# DEBUGSS_WRAP_CSTPIU_CFG_0_000720004000h register map
Vendor: Texas Instruments
Peripheral module from a debugger description file (folder AM275x).
Registers are 32-bit, read-only, reset 0x0 unless marked. A register's access mark holds for its fields unless they carry their own. Offsets are as the file gives them; lines under a group give offsets from that group; [hi:lo] are bit positions; {n}, {i} and the like mark numbered series; 'fields as' and 'values as' point back to an identical list; <NAME> marks a mode.

## cstpiu_cfg_0
0x00 CSTPIU_CFG_0_SUPPORTSIZE reset 0xFFFFFFFF — This register indicates how many trace pins are available for export. One pin per bit, right justified
  [31:0] SUPPORTSIZEREG
0x04 CSTPIU_CFG_0_CURPORTSIZE rw reset 0x1 — The Current Port Size Register has the same format as the Supported Port Sizes register but only one bit is set, and all others must be zero
  [31:0] CURRENTPORTSIZE
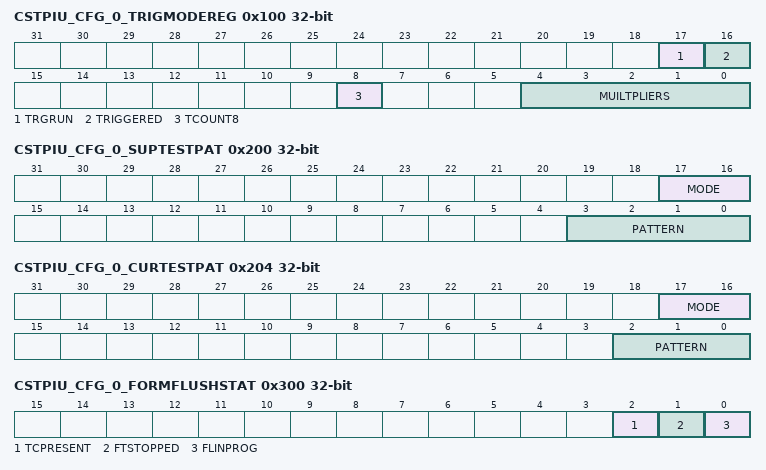
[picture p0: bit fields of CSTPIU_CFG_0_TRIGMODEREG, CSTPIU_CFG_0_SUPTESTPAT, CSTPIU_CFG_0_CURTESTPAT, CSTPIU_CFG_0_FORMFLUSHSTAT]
0x100 CSTPIU_CFG_0_TRIGMODEREG — This register indicates the implemented Trigger Counter multipliers and other supported features of the trigger system
  [17] TRGRUN — Trigger Counter running. A trigger has occurred but the counter is not at zero.
  [16] TRIGGERED — A trigger has occurred and the counter has reached zero.
  [8] TCOUNT8 — An 8-bit wide counter register implemented.
  [4:0] MUILTPLIERS — Multiply the Trigger Counter by 2, 4, 16, 256, 64K supported. Each bit is a mpy value.
0x104 CSTPIU_CFG_0_TRIGCTRREG access per field
  [7:0] TRIGCOUNT rw — 8-bit counter value for the number of words to be output from the formatter before a trigger is inserted.
0x108 CSTPIU_CFG_0_TRIGMPYREG access per field
  [4:0] MULTIPLIER rw — Trigger multiply value bit0=x2, bit1=x4, bit2=x16, bit3=x256, bit4=x64K.
0x200 CSTPIU_CFG_0_SUPTESTPAT — This register displays the supported patterns and modes for calibration
  [17:16] MODE — bit 16 is Timed Mode, bit 17 is continuous mode
  [3:0] PATTERN — bit0=Walking 1 pattern, bit1=walking 0, bit2=AA/55 pattern, bit3=FF/00 pattern
0x204 CSTPIU_CFG_0_CURTESTPAT access per field — This register displays the supported patterns and modes for calibration
  [17:16] MODE rw — Select the Pattern Timer Mode, see Supported Patterns reg
  [2:0] PATTERN rw — Select the pattern to run, set Supported Patterns Reg
0x208 CSTPIU_CFG_0_TESTPATCNT access per field — This register displays the supported patterns and modes for calibration
  [7:0] PATTERNCOUNT rw — Number of clocks a pattern should run before going to the next pattern
0x300 CSTPIU_CFG_0_FORMFLUSHSTAT — This register displays the supported patterns and modes for calibration
  [2] TCPRESENT — If this bit is set then TRACECTL is present. If no TRACECTL pin is present, then the data formatter must be used and only in continuous mode
  [1] FTSTOPPED — Formatter stopped. The formatter has received a stop request signal and all trace data and post-amble has been output.
  [0] FLINPROG — Flush In Progress. This is an indication of the current state of AFVALIDS.
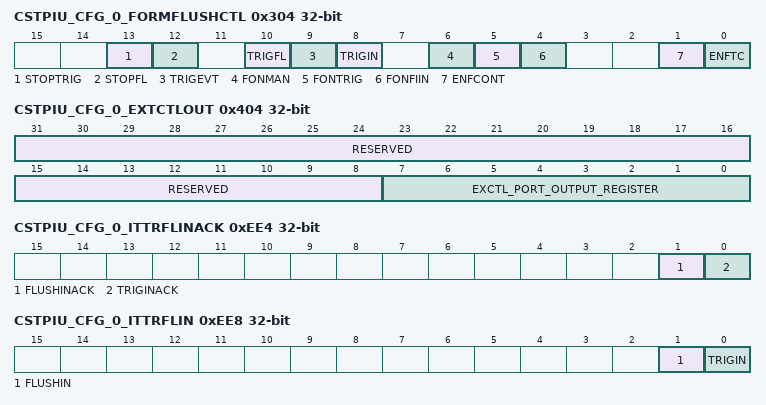
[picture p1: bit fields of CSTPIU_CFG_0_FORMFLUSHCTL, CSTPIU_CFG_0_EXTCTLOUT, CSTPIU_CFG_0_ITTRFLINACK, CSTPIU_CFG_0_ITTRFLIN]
0x304 CSTPIU_CFG_0_FORMFLUSHCTL access per field — This register controls the generation of stop, trigger, and flush events.
  [13] STOPTRIG rw — Stop the formatter after a Trigger Event is observed
  [12] STOPFL rw — Stop the formatter after a flush completes [return of AFREADYS].
  [10] TRIGFL rw — Indicates a trigger on Flush completion on AFREADYS being returned
  [9] TRIGEVT rw — Indicate a trigger on a Trigger Event.
  [8] TRIGIN rw — Indicate a trigger on TRIGIN being asserted.
  [6] FONMAN rw — Manually generate a flush of the system. It is cleared when this flush has been serviced.
  [5] FONTRIG rw — Generate flush using Trigger event
  [4] FONFIIN rw — Generate flush using the FLUSHIN interface.
  [1] ENFCONT rw — Continuous Formatting. Embed in trigger packets and indicate null cycles using Sync packets
  [0] ENFTC rw — Enable Formatting. Do not embed Triggers into the formatted stream
0x308 CSTPIU_CFG_0_FORMSYNCCTR access per field reset 0x40 — This counter is the number of formatter frames since the last synchronization packet of 128 bits, and is a 12-bit counter with a maximum count value of 4096
  [11:0] CYCCOUNT rw — 12-bit counter value to indicate the number of complete frames between full sync packets.
0x400 CSTPIU_CFG_0_EXTCTLIN — This register inputs data from an external port (if used)
  [7:0] EXCTL_PORT_INPUT_REGISTER
0x404 CSTPIU_CFG_0_EXTCTLOUT rw — This register is output to an external port (if used)
  [31:8] RESERVED — returns 0
  [7:0] EXCTL_PORT_OUTPUT_REGISTER
0xEE4 CSTPIU_CFG_0_ITTRFLINACK wo — Integration Test Trigger In and Flush In Acknowledge.
  [1] FLUSHINACK — Writing this register sets the value of FLUSHINACK. Reading it returns the value of FLUSHINACK.
  [0] TRIGINACK — Writing this register sets the value of TRIGINACK. Reading it returns the value of TRIGINACK.
0xEE8 CSTPIU_CFG_0_ITTRFLIN — Integration Test Trigger In and Flush In Register.
  [1] FLUSHIN — Reads the value of FlushIn
  [0] TRIGIN — Reads the value of Trigin
0xEEC CSTPIU_CFG_0_ITATBDATA0 — Integration Test ATB Data Register 0
  [32:5] RESERVED — return 0
  [4] ATDATA_31 — Reads the value of atdatas[31]
  [3] ATDATA_23 — Reads the value of atdatas[23]
  [2] ATDATA_15 — Reads the value of atdatas[15]
  [1] ATDATA_7 — Reads the value of atdatas[7]
  [0] ATDATA_0 — Reads the value of atdatas[0]
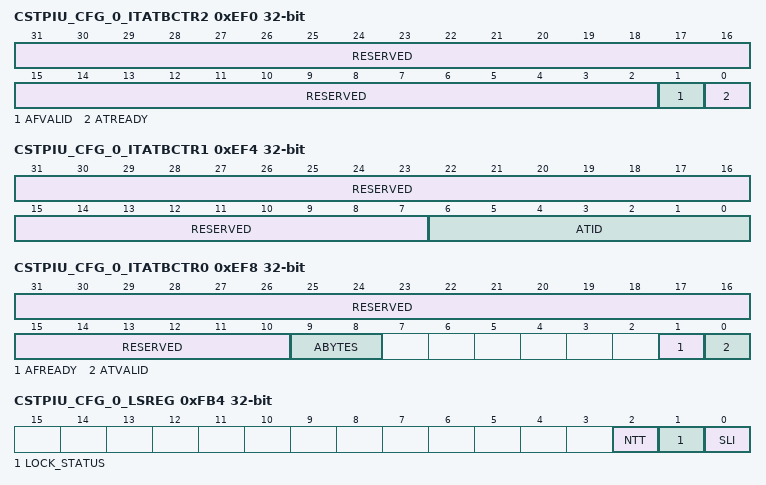
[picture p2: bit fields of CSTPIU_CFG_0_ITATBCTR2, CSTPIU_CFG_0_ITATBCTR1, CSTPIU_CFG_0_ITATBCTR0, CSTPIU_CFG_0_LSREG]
0xEF0 CSTPIU_CFG_0_ITATBCTR2 access per field — Integration Test ATB Control Register 2.
  [31:2] RESERVED ro — return 0
  [1] AFVALID wo — Sets the value of afvalid
  [0] ATREADY wo — Sets the value of atready
0xEF4 CSTPIU_CFG_0_ITATBCTR1 — Integration Test ATB Control Register 1.
  [31:7] RESERVED — returns 0
  [6:0] ATID — Reads the value of atids
0xEF8 CSTPIU_CFG_0_ITATBCTR0 — Integration Test ATB Control Register 0.
  [31:10] RESERVED — Reads return 0 Reads return 0
  [9:8] ABYTES — Reads the value of the atbytess
  [1] AFREADY — Reads the value of afreadys
  [0] ATVALID — Reads the value of atvalids
0xF00 CSTPIU_CFG_0_INTCTRL access per field — Integration Mode Register
  [0] IME rw — Integration Mode Enable.
0xFA0 CSTPIU_CFG_0_CTSET access per field reset 0xF — Claim Tag Set Register
  [3:0] CLAIM_TAG_SET rw
0xFA4 CSTPIU_CFG_0_CTCLR access per field — Claim Tag Clear Register
  [3:0] CLAIM_TAG_CLEAR rw
0xFB0 CSTPIU_CFG_0_LAREG wo — Software must write 0xCSACCE55 to this register in order for application to gain access to the other registers. If paddrdbg31 is high, this is ignored.
  [31:0] LOCK_ACCESS_REGISTER
0xFB4 CSTPIU_CFG_0_LSREG — The CTI implements two memory maps controlled through PADDRDBG31. When PADDRDBG31 is HIGH, the Lock Status Register reads as 0x0 indicating that no lock exists. When PADDRDBG31 is LOW, the Lock Status Register reads as 0x3 from reset. This indicates a 32-bit lock access mechanism is present and is locked
  [2] NTT — Register size Indicator. Always 0. Indiates that the LAR is implemented as 32-bit
  [1] LOCK_STATUS — The CTI implements two memory maps controlled through PADDRDBG31. When PADDRDBG31 is HIGH, the Lock Status Register reads as 0x0 indicating that no lock exists. When PADDRDBG31 is LOW, the Lock Status Register reads as 0x3 from reset. This indicates a 32-bit lock access mechanism is present and is locked. Application must write to the LAREG to gain access.
  [0] SLI — Software Lock Implemented. Indicates that a lock control mechanism is present from this interface
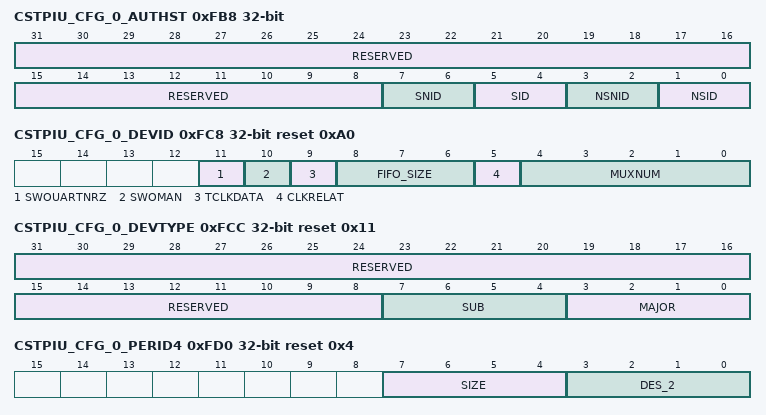
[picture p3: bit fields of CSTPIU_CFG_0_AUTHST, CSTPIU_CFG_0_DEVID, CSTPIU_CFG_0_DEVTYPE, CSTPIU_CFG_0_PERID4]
0xFB8 CSTPIU_CFG_0_AUTHST — Reports the required security level.
  [31:8] RESERVED — Reads return 0
  [7:6] SNID — Indicates the security level for Secure non-invasive debug
  [5:4] SID — Indicates the security level for Secure invasive debug
  [3:2] NSNID — Indicates the security level for Non-secure non-invasive debug.
  [1:0] NSID — Indicates the security level for Non-secure invasive debug.
0xFC8 CSTPIU_CFG_0_DEVID reset 0xA0 — This shows the characteristics of the TPIU
  [11] SWOUARTNRZ — Indicates Serial Wire Output [UART/NRZ] is not supported. Defaul = 0
  [10] SWOMAN — Indicates Serial Wire Output [Manchester] is not supported. Default = 0
  [9] TCLKDATA — Indicates trace clock + data is supported.
  [8:6] FIFO_SIZE — FIFO size in powers of 2. A value of 2 gives a FIFO size of 4 entries, 16 bytes. Default is3'b010
  [5] CLKRELAT — Indicates the relationship between ATCLK and TRACECLKIN. 0x1 indicates asynchronous.
  [4:0] MUXNUM — When nonzero this value indicates the type/number of ATB multiplexing present on the input to the ATB. Currently only 0x00 is supported, that is, no multiplexing present.
0xFCC CSTPIU_CFG_0_DEVTYPE reset 0x11 — Device Type Identifier Register
  [31:8] RESERVED — Reserveed, returns 0
  [7:4] SUB — Sub-classification of the type of the debug component as specified in the Arm Architecture Specification within the major classification as specified in the MAJOR field
  [3:0] MAJOR — Major classification of the type of the debug component as specified in the Arm Architecture Specification for this debug and trace component
0xFD0 CSTPIU_CFG_0_PERID4 reset 0x4 — Peripheral ID4 Register
  [7:4] SIZE — Always 0b0000. Indicates that the device only occupies 4KB memory
  [3:0] DES_2 — PIDR1.DES_0, PIDR2.DES_1, and PIDR4.DES2 identify the designer of the component
0xFE0 CSTPIU_CFG_0_PERID0 reset 0x12 — Peripheral ID0 Register
  [7:0] PART_0 — Perpiheral ID 0, returns the 12-bit part number of the component.
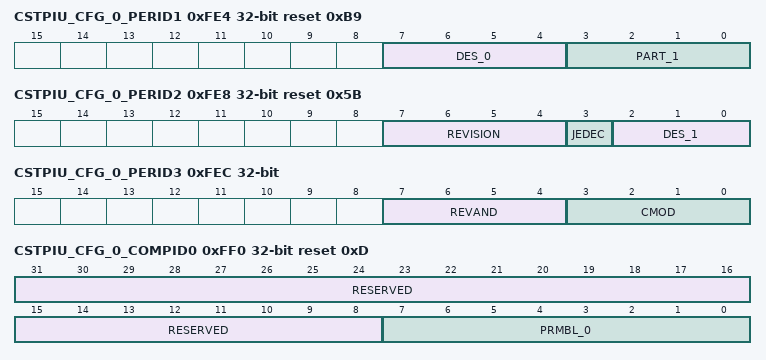
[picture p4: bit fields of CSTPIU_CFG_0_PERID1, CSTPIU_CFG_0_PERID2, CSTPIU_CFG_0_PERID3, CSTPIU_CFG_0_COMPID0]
0xFE4 CSTPIU_CFG_0_PERID1 reset 0xB9 — Peripheral ID1 Register
  [7:4] DES_0 — return 0xB. Together, PIDR1.DES_0, PIDR2.DES_1, and PIDR4.DES_2 identify the designer of the component
  [3:0] PART_1 — Peripheral ID 1, returns 0x9
0xFE8 CSTPIU_CFG_0_PERID2 reset 0x5B — Peripheral ID2 Register
  [7:4] REVISION — always return 0x5
  [3] JEDEC — always return 1. Indicates that the JEDEC-assigned designer ID is used
  [2:0] DES_1 — Return 0x3. Together, PIDR1.DES_0, PIDR2.DES_1, and PIDR4.DES_2 identify the designer of the component
0xFEC CSTPIU_CFG_0_PERID3 — Peripheral ID3 Register
  [7:4] REVAND — return 0000. Indicates that there are no extra fixes to this component
  [3:0] CMOD — Customer Modified. returns 0x00 to indicate that the customer has not modified this component.
0xFF0 CSTPIU_CFG_0_COMPID0 reset 0xD — Component ID0 Register
  [31:8] RESERVED — Read returns 0
  [7:0] PRMBL_0 — Preamble_0. return 0xD. Component ID register contains bits 7:0 of the component ID
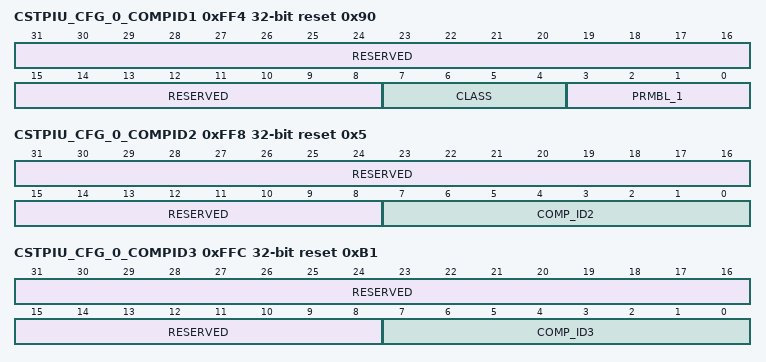
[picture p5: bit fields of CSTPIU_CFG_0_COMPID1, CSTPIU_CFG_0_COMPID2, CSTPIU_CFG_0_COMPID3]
0xFF4 CSTPIU_CFG_0_COMPID1 reset 0x90 — Component ID1 Register
  [31:8] RESERVED — Read returns 0
  [7:4] CLASS — Return 0x9. Class of the component. Contain bits [15:12] of the component ID.
  [3:0] PRMBL_1 — Component ID register contains bits16:8 of the component ID
0xFF8 CSTPIU_CFG_0_COMPID2 reset 0x5 — Component ID2 Register
  [31:8] RESERVED — Returns 0
  [7:0] COMP_ID2 — A component identification register, that indicates that the identification registers are present. This register also indicates the component class.
0xFFC CSTPIU_CFG_0_COMPID3 reset 0xB1 — Component ID3 Register
  [31:8] RESERVED — returns 0 when read
  [7:0] COMP_ID3 — A component identification register, that indicates that the identification registers are present. This register also indicates the component class.
